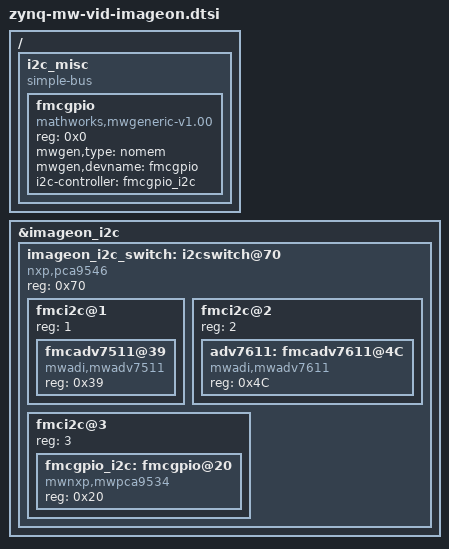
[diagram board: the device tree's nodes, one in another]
/{
    i2c_misc {
        compatible = "simple-bus";
		#address-cells = <0x1>;
		#size-cells = <0x0>;

        fmcgpio {
            compatible = "mathworks,mwgeneric-v1.00";       
            reg = <0x0>;    
            mwgen,type = "nomem";            
            mwgen,devname = "fmcgpio";            
            i2c-controller = <&fmcgpio_i2c>;
        };
    };
};

&imageon_i2c {
    status = "okay";

	imageon_i2c_switch: i2cswitch@70 {
			compatible = "nxp,pca9546";
			#address-cells = <1>;
			#size-cells = <0>;
			reg = <0x70>;            
		
			fmci2c@1 {
				#address-cells = <1>;
				#size-cells = <0>;
				reg = <1>;
				
				fmcadv7511@39 {
					compatible = "mwadi,mwadv7511";
					reg = <0x39>;
				};
				
			};
			fmci2c@2 {
				#address-cells = <1>;
				#size-cells = <0>;
				reg = <2>;

				adv7611: fmcadv7611@4C {
					compatible = "mwadi,mwadv7611";
					reg = <0x4C>;
				};

			};
			fmci2c@3 {
				#address-cells = <1>;
				#size-cells = <0>;
				reg = <3>;
				
				fmcgpio_i2c: fmcgpio@20 {
					compatible = "mwnxp,mwpca9534";
					reg = <0x20>;
				};
			};
		};
};
